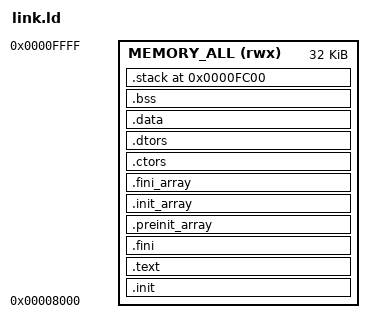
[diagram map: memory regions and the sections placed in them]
/* This file was "borrowed" from the CH32V003 SDK */
OUTPUT_ARCH("riscv")
ENTRY(_start)

__stack_size = 1024;
PROVIDE(_stack_size = __stack_size);

MEMORY
{
    MEMORY_ALL (rwx) : ORIGIN = 0x08000, LENGTH = 32K
}

SECTIONS
{
    .init :
    {
        _sinit = .;
        . = ALIGN(4);
        KEEP(*(SORT_NONE(.init)))
        . = ALIGN(4);
        _einit = .;
    } > MEMORY_ALL

    .text :
    {
        . = ALIGN(4);
        *(.text)
        *(.text.*)
        *(.rodata)
        *(.rodata*)
        *(.gnu.linkonce.t.*)
        . = ALIGN(4);
    } > MEMORY_ALL

    .fini :
        {
          KEEP(*(SORT_NONE(.fini)))
      . = ALIGN(4);
    } > MEMORY_ALL

    PROVIDE( _etext = . );
    PROVIDE( _eitcm = . );

    .preinit_array :
    {
        PROVIDE_HIDDEN (__preinit_array_start = .);
        KEEP (*(.preinit_array))
        PROVIDE_HIDDEN (__preinit_array_end = .);
    } > MEMORY_ALL

    .init_array :
    {
        PROVIDE_HIDDEN (__init_array_start = .);
        KEEP (*(SORT_BY_INIT_PRIORITY(.init_array.*) SORT_BY_INIT_PRIORITY(.ctors.*)))
        KEEP (*(.init_array EXCLUDE_FILE (*crtbegin.o *crtbegin?.o *crtend.o *crtend?.o ) .ctors))
        PROVIDE_HIDDEN (__init_array_end = .);
    } > MEMORY_ALL

    .fini_array :
    {
        PROVIDE_HIDDEN (__fini_array_start = .);
        KEEP (*(SORT_BY_INIT_PRIORITY(.fini_array.*) SORT_BY_INIT_PRIORITY(.dtors.*)))
        KEEP (*(.fini_array EXCLUDE_FILE (*crtbegin.o *crtbegin?.o *crtend.o *crtend?.o ) .dtors))
        PROVIDE_HIDDEN (__fini_array_end = .);
    } > MEMORY_ALL

    .ctors :
    {
        KEEP (*crtbegin.o(.ctors))
        KEEP (*crtbegin?.o(.ctors))
        KEEP (*(EXCLUDE_FILE (*crtend.o *crtend?.o ) .ctors))
        KEEP (*(SORT(.ctors.*)))
        KEEP (*(.ctors))
    } > MEMORY_ALL

    .dtors :
    {
        KEEP (*crtbegin.o(.dtors))
        KEEP (*crtbegin?.o(.dtors))
        KEEP (*(EXCLUDE_FILE (*crtend.o *crtend?.o ) .dtors))
        KEEP (*(SORT(.dtors.*)))
        KEEP (*(.dtors))
    } > MEMORY_ALL

    .data :
    {
        . = ALIGN(4);
        PROVIDE( _sdata = .);
        *(.gnu.linkonce.r.*)
        *(.data .data.*)
        *(.gnu.linkonce.d.*)
        . = ALIGN(8);
        PROVIDE( __global_pointer$ = . + 0x800 );
        *(.sdata .sdata.*)
        *(.sdata2*)
        *(.gnu.linkonce.s.*)
        . = ALIGN(8);
        *(.srodata.cst16)
        *(.srodata.cst8)
        *(.srodata.cst4)
        *(.srodata.cst2)
        *(.srodata .srodata.*)
        . = ALIGN(4);
        PROVIDE( _edata = .);
    } > MEMORY_ALL

    .bss :
    {
        . = ALIGN(4);
        PROVIDE( _sbss = .);
        *(.sbss*)
        *(.gnu.linkonce.sb.*)
        *(.bss*)
        *(.gnu.linkonce.b.*)
        *(COMMON*)
        . = ALIGN(4);
        PROVIDE( _ebss = .);
    } > MEMORY_ALL

    PROVIDE( _end = _ebss);
    PROVIDE( end = . );

    .stack ORIGIN(MEMORY_ALL) + LENGTH(MEMORY_ALL) - __stack_size :
    {
        PROVIDE( _heap_end = . );
        . = ALIGN(4);
        PROVIDE(_susrstack = . );
        . = . + __stack_size;
        PROVIDE( _eusrstack = .);
    } > MEMORY_ALL
}
